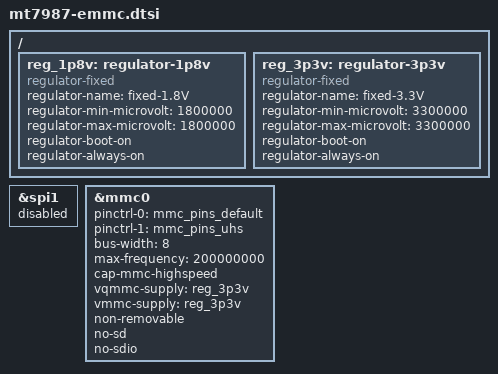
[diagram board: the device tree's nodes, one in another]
/* SPDX-License-Identifier: (GPL-2.0-only OR MIT) */

#include "mt7987-pinctrl.dtsi"

/ {
	reg_1p8v: regulator-1p8v {
		compatible = "regulator-fixed";
		regulator-name = "fixed-1.8V";
		regulator-min-microvolt = <1800000>;
		regulator-max-microvolt = <1800000>;
		regulator-boot-on;
		regulator-always-on;
	};

	reg_3p3v: regulator-3p3v {
		compatible = "regulator-fixed";
		regulator-name = "fixed-3.3V";
		regulator-min-microvolt = <3300000>;
		regulator-max-microvolt = <3300000>;
		regulator-boot-on;
		regulator-always-on;
	};	
};

/* Disable spi1 node since MSDC and spi1 share pins on MT7987. */
&spi1 {
	status = "disabled";
};

&mmc0 {
	pinctrl-names = "default", "state_uhs";
	pinctrl-0 = <&mmc_pins_default>;
	pinctrl-1 = <&mmc_pins_uhs>;
	bus-width = <8>;
	max-frequency = <200000000>;
	cap-mmc-highspeed;
	vqmmc-supply = <&reg_3p3v>;
	vmmc-supply = <&reg_3p3v>;
	non-removable;
	no-sd;
	no-sdio;
	status = "okay";
};
